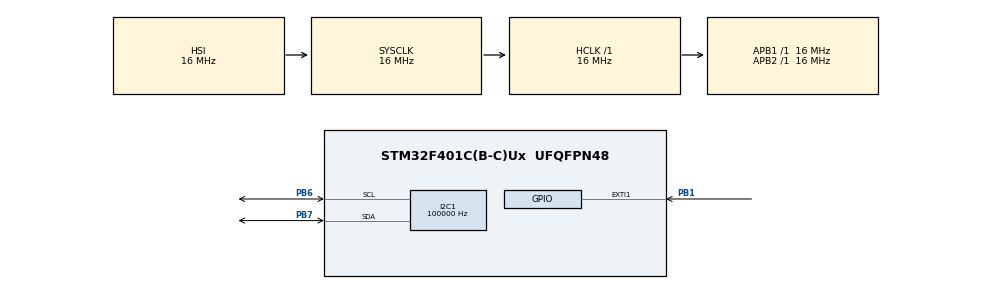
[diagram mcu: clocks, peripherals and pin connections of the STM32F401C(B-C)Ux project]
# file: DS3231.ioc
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I2C1.ClockSpeed=100000
Mcu.Family=STM32F4
Mcu.Name=STM32F401C(B-C)Ux
Mcu.Package=UFQFPN48
NVIC.EXTI1_IRQn=true\:5\:0\:true\:false\:true\:true\:true\:true
NVIC.I2C1_ER_IRQn=true\:0\:0\:false\:false\:true\:true\:true\:true
NVIC.I2C1_EV_IRQn=true\:0\:0\:false\:false\:true\:true\:true\:true
NVIC.PriorityGroup=NVIC_PRIORITYGROUP_4
PB1.GPIO_ModeDefaultEXTI=GPIO_MODE_IT_FALLING
PB1.GPIO_PuPd=GPIO_PULLDOWN
PB1.Signal=GPXTI1
PB6.Mode=I2C
PB6.Signal=I2C1_SCL
PB7.Mode=I2C
PB7.Signal=I2C1_SDA
ProjectManager.HeapSize=0x200
ProjectManager.StackSize=0x400
ProjectManager.TargetToolchain=STM32CubeIDE
RCC.AHBFreq_Value=16000000
RCC.APB1Freq_Value=16000000
RCC.APB1TimFreq_Value=16000000
RCC.APB2Freq_Value=16000000
RCC.APB2TimFreq_Value=16000000
RCC.CortexFreq_Value=16000000
RCC.HCLKFreq_Value=16000000
RCC.HSE_VALUE=25000000
RCC.HSI_VALUE=16000000
RCC.LSE_VALUE=32768
RCC.SYSCLKFreq_VALUE=16000000
RCC.VCOOutputFreq_Value=192000000
board=custom

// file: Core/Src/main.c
/* USER CODE BEGIN Header */
/**
  ******************************************************************************
  * @file           : main.c
  * @brief          : Main program body
  ******************************************************************************
  * @attention
  *
  * Copyright (c) 2026 STMicroelectronics.
  * All rights reserved.
  *
  * This software is licensed under terms that can be found in the LICENSE file
  * in the root directory of this software component.
  * If no LICENSE file comes with this software, it is provided AS-IS.
  *
  ******************************************************************************
  */
/* USER CODE END Header */
#include "main.h"
#include "ds3231.h"
#include "eeprom.h"

/* USER CODE BEGIN PD */
#define DS3231_WRİTE_ADRESS				0xD0
#define DS3231_READ_ADRESS 				0xD1

/* USER CODE END PD */

I2C_HandleTypeDef hi2c1;

/* USER CODE BEGIN PV */

DS3231_Time_t ds3231_Time;
DS3231_Alarm_t ds3231_Alarm;
uint8_t val = 0;
uint8_t control_reg_val = 0x05; // INTCN=1, A1IE=1
uint8_t status_reg_reset = 0x00;
uint8_t writeData[32];
uint8_t readData[32];
/* USER CODE END PV */

void SystemClock_Config(void);
static void MX_GPIO_Init(void);
static void MX_I2C1_Init(void);

int main(void)
{

  /* MCU Configuration--------------------------------------------------------*/

  /* Reset of all peripherals, Initializes the Flash interface and the Systick. */
  HAL_Init();

  /* Configure the system clock */
  SystemClock_Config();

  /* Initialize all configured peripherals */
  MX_GPIO_Init();
  MX_I2C1_Init();
  /* USER CODE BEGIN 2 */

  //control Reg write for activate the alarm 1 and other config

/*
EEPROM WRİTE READ
 ****************************
  for(int i = 0; i<32 ; i++)
  {
	  writeData[i] = i;
  }

  Write_EEPROM(0x00, writeData, 32);
  Read_EEPROM(0x00, readData, 32);
*/

 /*
RTC AND ALARM
   * *********************************************** *
  HAL_I2C_Mem_Write(&hi2c1, 0xD0, 0x0E, 1, &control_reg_val, 1, HAL_MAX_DELAY);
  //status Reg write for set the alarm1 flag 0
  HAL_I2C_Mem_Write(&hi2c1, 0xD0, 0x0F, 1, &status_reg_reset, 1, HAL_MAX_DELAY);
  DS3231_Set_Time(50, 59, 23, 7, 31, 12, 26);
  DS3231_Set_Alarm(10,0, 0, 1);
  ds3231_Alarm = DS3231_Get_Alarm();
  * ************************************************* *
  */

  /* USER CODE END 2 */

  /* Infinite loop */
  while (1)
  {

    /* USER CODE BEGIN 3 */

	  /*
FOR RTC AND ALARM
	 	 *** ***************************
	 ds3231_Time = DS3231_Get_Time();
	 HAL_Delay(100);
	   	  ******************************
	   */

  }
  /* USER CODE END 3 */
}

void SystemClock_Config(void)
{
  RCC_OscInitTypeDef RCC_OscInitStruct = {0};
  RCC_ClkInitTypeDef RCC_ClkInitStruct = {0};

  /** Configure the main internal regulator output voltage
  */
  __HAL_RCC_PWR_CLK_ENABLE();
  __HAL_PWR_VOLTAGESCALING_CONFIG(PWR_REGULATOR_VOLTAGE_SCALE2);

  /** Initializes the RCC Oscillators according to the specified parameters
  * in the RCC_OscInitTypeDef structure.
  */
  RCC_OscInitStruct.OscillatorType = RCC_OSCILLATORTYPE_HSI;
  RCC_OscInitStruct.HSIState = RCC_HSI_ON;
  RCC_OscInitStruct.HSICalibrationValue = RCC_HSICALIBRATION_DEFAULT;
  RCC_OscInitStruct.PLL.PLLState = RCC_PLL_NONE;
  if (HAL_RCC_OscConfig(&RCC_OscInitStruct) != HAL_OK)
  {
    Error_Handler();
  }

  /** Initializes the CPU, AHB and APB buses clocks
  */
  RCC_ClkInitStruct.ClockType = RCC_CLOCKTYPE_HCLK|RCC_CLOCKTYPE_SYSCLK
                              |RCC_CLOCKTYPE_PCLK1|RCC_CLOCKTYPE_PCLK2;
  RCC_ClkInitStruct.SYSCLKSource = RCC_SYSCLKSOURCE_HSI;
  RCC_ClkInitStruct.AHBCLKDivider = RCC_SYSCLK_DIV1;
  RCC_ClkInitStruct.APB1CLKDivider = RCC_HCLK_DIV1;
  RCC_ClkInitStruct.APB2CLKDivider = RCC_HCLK_DIV1;

  if (HAL_RCC_ClockConfig(&RCC_ClkInitStruct, FLASH_LATENCY_0) != HAL_OK)
  {
    Error_Handler();
  }
}

static void MX_I2C1_Init(void)
{

  hi2c1.Instance = I2C1;
  hi2c1.Init.ClockSpeed = 100000;
  hi2c1.Init.DutyCycle = I2C_DUTYCYCLE_2;
  hi2c1.Init.OwnAddress1 = 0;
  hi2c1.Init.AddressingMode = I2C_ADDRESSINGMODE_7BIT;
  hi2c1.Init.DualAddressMode = I2C_DUALADDRESS_DISABLE;
  hi2c1.Init.OwnAddress2 = 0;
  hi2c1.Init.GeneralCallMode = I2C_GENERALCALL_DISABLE;
  hi2c1.Init.NoStretchMode = I2C_NOSTRETCH_DISABLE;
  if (HAL_I2C_Init(&hi2c1) != HAL_OK)
  {
    Error_Handler();
  }

}

static void MX_GPIO_Init(void)
{
  GPIO_InitTypeDef GPIO_InitStruct = {0};

  /* GPIO Ports Clock Enable */
  __HAL_RCC_GPIOB_CLK_ENABLE();

  /*Configure GPIO pin : PB1 */
  GPIO_InitStruct.Pin = GPIO_PIN_1;
  GPIO_InitStruct.Mode = GPIO_MODE_IT_FALLING;
  GPIO_InitStruct.Pull = GPIO_PULLDOWN;
  HAL_GPIO_Init(GPIOB, &GPIO_InitStruct);

  /* EXTI interrupt init*/
  HAL_NVIC_SetPriority(EXTI1_IRQn, 5, 0);
  HAL_NVIC_EnableIRQ(EXTI1_IRQn);

}

void Error_Handler(void)
{
  __disable_irq();
  while (1)
  {
  }
}
